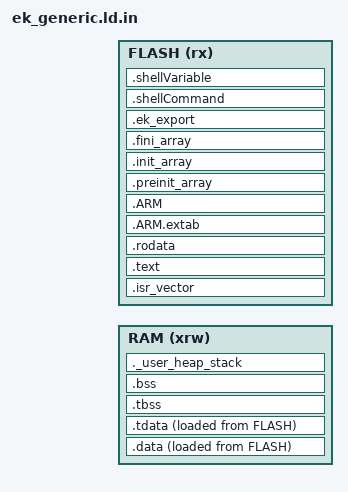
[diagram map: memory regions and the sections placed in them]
/*
******************************************************************************
**
**  File        : ek_generic.ld.in
**
**  Abstract    : 由 CMake configure_file 自动生成的通用链接脚本模板
**                请勿手动编辑生成后的 .ld 文件，修改此 .ld.in 模板
**
**  Memory      : 通过各 MCU 子目录的 CMakeLists.txt 配置以下变量：
**
**    必选：
**      EK_FLASH_ORIGIN / EK_FLASH_LENGTH   - Flash 起始地址和大小
**      EK_RAM_ORIGIN   / EK_RAM_LENGTH     - RAM 起始地址和大小
**
**    可选（不设置则对应区域和段完全省略）：
**      EK_CCMRAM_ORIGIN / EK_CCMRAM_LENGTH - CCM-RAM 起始地址和大小
**      EK_SDRAM1_ORIGIN / EK_SDRAM1_LENGTH - SDRAM1 起始地址和大小
**      EK_SDRAM2_ORIGIN / EK_SDRAM2_LENGTH - SDRAM2 起始地址和大小
**
**    可选（有默认值）：
**      EK_MIN_HEAP_SIZE  - 最小堆大小（默认 0x200）
**      EK_MIN_STACK_SIZE - 最小栈大小（默认 0x400）
**
******************************************************************************
*/

/* Entry Point */
ENTRY(Reset_Handler)

/* Highest address of the user mode stack */
_estack = ORIGIN(RAM) + LENGTH(RAM);    /* end of RAM */
_sp = _estack;                          /* GD32 startup alias */

/* Generate a link error if heap and stack don't fit into RAM */
_Min_Heap_Size  = @EK_MIN_HEAP_SIZE@;   /* required amount of heap  */
_Min_Stack_Size = @EK_MIN_STACK_SIZE@;  /* required amount of stack */

/* Specify the memory areas */
MEMORY
{
RAM    (xrw) : ORIGIN = @EK_RAM_ORIGIN@,   LENGTH = @EK_RAM_LENGTH@
FLASH  (rx)  : ORIGIN = @EK_FLASH_ORIGIN@, LENGTH = @EK_FLASH_LENGTH@
@EK_LD_CCMRAM_REGION@
@EK_LD_SDRAM1_REGION@
@EK_LD_SDRAM2_REGION@
}

/* Define output sections */
SECTIONS
{
  /* The startup code goes first into FLASH */
  .isr_vector :
  {
    . = ALIGN(4);
    KEEP(*(.isr_vector)) /* Startup code - STM32 */
    KEEP(*(.vectors))    /* Startup code - GD32  */
    . = ALIGN(4);
  } >FLASH

  /* The program code and other data goes into FLASH */
  .text :
  {
    . = ALIGN(4);
    *(.text)           /* .text sections (code) */
    *(.text*)          /* .text* sections (code) */
    *(.glue_7)         /* glue arm to thumb code */
    *(.glue_7t)        /* glue thumb to arm code */
    *(.eh_frame)

    KEEP (*(.init))
    KEEP (*(.fini))

    . = ALIGN(4);
    _etext = .;        /* define a global symbols at end of code */
  } >FLASH

  /* Constant data goes into FLASH */
  .rodata :
  {
    . = ALIGN(4);
    *(.rodata)         /* .rodata sections (constants, strings, etc.) */
    *(.rodata*)        /* .rodata* sections (constants, strings, etc.) */
    . = ALIGN(4);
  } >FLASH

  .ARM.extab (READONLY) :
  {
    . = ALIGN(4);
    *(.ARM.extab* .gnu.linkonce.armextab.*)
    . = ALIGN(4);
  } >FLASH

  .ARM (READONLY) :
  {
    . = ALIGN(4);
    __exidx_start = .;
    *(.ARM.exidx*)
    __exidx_end = .;
    . = ALIGN(4);
  } >FLASH

  .preinit_array (READONLY) :
  {
    . = ALIGN(4);
    PROVIDE_HIDDEN (__preinit_array_start = .);
    KEEP (*(.preinit_array*))
    PROVIDE_HIDDEN (__preinit_array_end = .);
    . = ALIGN(4);
  } >FLASH

  .init_array (READONLY) :
  {
    . = ALIGN(4);
    PROVIDE_HIDDEN (__init_array_start = .);
    KEEP (*(SORT(.init_array.*)))
    KEEP (*(.init_array*))
    PROVIDE_HIDDEN (__init_array_end = .);
    . = ALIGN(4);
  } >FLASH

  .fini_array (READONLY) :
  {
    . = ALIGN(4);
    PROVIDE_HIDDEN (__fini_array_start = .);
    KEEP (*(SORT(.fini_array.*)))
    KEEP (*(.fini_array*))
    PROVIDE_HIDDEN (__fini_array_end = .);
    . = ALIGN(4);
  } >FLASH

  /* EmbeddedKit 自动导出段 */
  .ek_export :
  {
    . = ALIGN(4);
    _ek_export_fn_start = .;
    KEEP(*(SORT(.ek_export_fn*)))
    . = ALIGN(4);
    _ek_export_fn_end = .;
  } >FLASH

  /* letter_shell 命令表段 */
  .shellCommand :
  {
    . = ALIGN(4);
    _shell_command_start = .;
    KEEP(*(SORT(.shellCommand*)))
    . = ALIGN(4);
    _shell_command_end = .;
  } >FLASH

  /* letter_shell 变量表段 */
  .shellVariable :
  {
    . = ALIGN(4);
    _shell_variable_start = .;
    KEEP(*(SORT(.shellVariable*)))
    . = ALIGN(4);
    _shell_variable_end = .;
  } >FLASH

@EK_LD_CCMRAM_SECTION@
  /* used by the startup to initialize data */
  _sidata = LOADADDR(.data);

  /* Initialized data sections goes into RAM, load LMA copy after code */
  .data :
  {
    . = ALIGN(4);
    _sdata = .;        /* create a global symbol at data start */
    *(.data)           /* .data sections */
    *(.data*)          /* .data* sections */
    *(.RamFunc)        /* .RamFunc sections */
    *(.RamFunc*)       /* .RamFunc* sections */

    . = ALIGN(4);
  } >RAM AT> FLASH

  /* Initialized TLS data section */
  .tdata : ALIGN(4)
  {
    *(.tdata .tdata.* .gnu.linkonce.td.*)
    . = ALIGN(4);
    _edata = .;        /* define a global symbol at data end */
    PROVIDE(__data_end  = .);
    PROVIDE(__tdata_end = .);
  } >RAM AT> FLASH

  PROVIDE( __tdata_start = ADDR(.tdata) );
  PROVIDE( __tdata_size  = __tdata_end - __tdata_start );

  PROVIDE( __data_start = ADDR(.data) );
  PROVIDE( __data_size  = __data_end - __data_start );

  PROVIDE( __tdata_source      = LOADADDR(.tdata) );
  PROVIDE( __tdata_source_end  = LOADADDR(.tdata) + SIZEOF(.tdata) );
  PROVIDE( __tdata_source_size = __tdata_source_end - __tdata_source );

  PROVIDE( __data_source      = LOADADDR(.data) );
  PROVIDE( __data_source_end  = __tdata_source_end );
  PROVIDE( __data_source_size = __data_source_end - __data_source );

  /* Uninitialized TLS data section */
  .tbss (NOLOAD) : ALIGN(4)
  {
    /* This is used by the startup in order to initialize the .bss section */
    _sbss        = .;         /* define a global symbol at bss start */
    __bss_start__ = _sbss;
    *(.tbss .tbss.*)
    . = ALIGN(4);
    PROVIDE( __tbss_end = . );
  } >RAM

  PROVIDE( __tbss_start  = ADDR(.tbss) );
  PROVIDE( __tbss_size   = __tbss_end - __tbss_start );
  PROVIDE( __tbss_offset = ADDR(.tbss) - ADDR(.tdata) );

  PROVIDE( __tls_base       = __tdata_start );
  PROVIDE( __tls_end        = __tbss_end );
  PROVIDE( __tls_size       = __tls_end - __tls_base );
  PROVIDE( __tls_align      = MAX(ALIGNOF(.tdata), ALIGNOF(.tbss)) );
  PROVIDE( __tls_size_align = (__tls_size + __tls_align - 1) & ~(__tls_align - 1) );
  PROVIDE( __arm32_tls_tcb_offset = MAX(8,  __tls_align) );
  PROVIDE( __arm64_tls_tcb_offset = MAX(16, __tls_align) );

  /* Uninitialized data section */
  .bss (NOLOAD) : ALIGN(4)
  {
    *(.bss)
    *(.bss*)
    *(COMMON)

    . = ALIGN(4);
    _ebss       = .;         /* define a global symbol at bss end */
    __bss_end__ = _ebss;
    PROVIDE( __bss_end = . );
  } >RAM

  PROVIDE( __non_tls_bss_start = ADDR(.bss) );
  PROVIDE( __bss_start         = __tbss_start );
  PROVIDE( __bss_size          = __bss_end - __bss_start );

  /* User_heap_stack section, used to check that there is enough RAM left */
  ._user_heap_stack (NOLOAD) :
  {
    . = ALIGN(8);
    PROVIDE ( end  = . );
    PROVIDE ( _end = . );
    . = . + _Min_Heap_Size;
    . = . + _Min_Stack_Size;
    . = ALIGN(8);
  } >RAM

  /* Remove information from the standard libraries */
  /DISCARD/ :
  {
    libc.a ( * )
    libm.a ( * )
    libgcc.a ( * )
  }

  .ARM.attributes 0 : { *(.ARM.attributes) }

@EK_LD_SDRAM1_SECTION@
@EK_LD_SDRAM2_SECTION@
}
